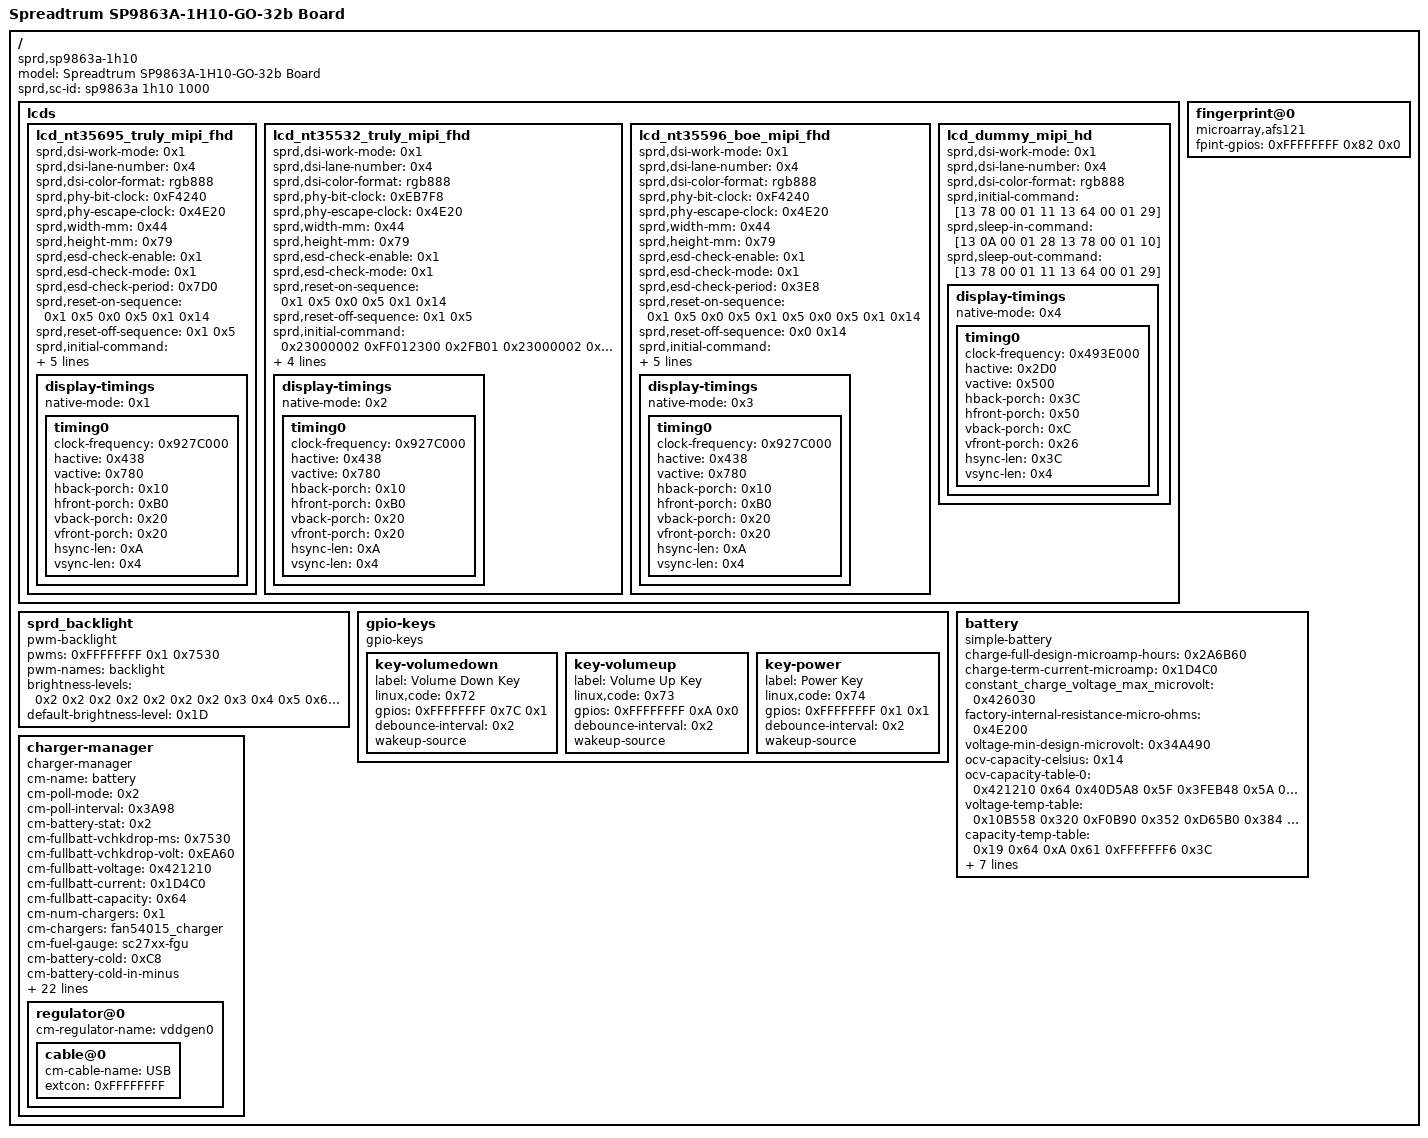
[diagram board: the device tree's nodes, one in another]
/dts-v1/;
// version: 17
// last_comp_version: 16
// boot_cpuid_phys: 0x0

/ {
    model = "Spreadtrum SP9863A-1H10-GO-32b Board";
    compatible = "sprd,sp9863a-1h10", "sprd,sc9863a";
    sprd,sc-id = "sp9863a 1h10 1000";
    fragment {
        target-path = "/";
        __overlay__ {
            lcds {
                lcd_nt35695_truly_mipi_fhd {
                    sprd,dsi-work-mode = <0x1>;
                    sprd,dsi-lane-number = <0x4>;
                    sprd,dsi-color-format = "rgb888";
                    sprd,phy-bit-clock = <0xF4240>;
                    sprd,phy-escape-clock = <0x4E20>;
                    sprd,width-mm = <0x44>;
                    sprd,height-mm = <0x79>;
                    sprd,esd-check-enable = <0x1>;
                    sprd,esd-check-mode = <0x1>;
                    sprd,esd-check-period = <0x7D0>;
                    sprd,reset-on-sequence = <0x1 0x5 0x0 0x5 0x1 0x14>;
                    sprd,reset-off-sequence = <0x1 0x5>;
                    sprd,initial-command = [23 00 00 02 FF 20 23 00 00 02 00 01 23 00 00 02 01 55 23 00 00 02 02 45 23 00 00 02 03 55 23 00 00 02 05 50 23 00 00 02 06 4A 23 00 00 02 07 24 23 00 00 02 08 0C 23 00 00 02 0B 87 23 00 00 02 0C 87 23 00 00 02 0E B0 23 00 00 02 0F B3 23 00 00 02 11 25 23 00 00 02 12 10 23 00 00 02 13 03 23 00 00 02 14 4A 23 00 00 02 15 12 23 00 00 02 16 12 23 00 00 02 30 01 23 00 00 02 58 82 23 00 00 02 59 00 23 00 00 02 5A 02 23 00 00 02 5B 00 23 00 00 02 5C 82 23 00 00 02 5D 82 23 00 00 02 5E 02 23 00 00 02 5F 02 23 00 00 02 72 31 23 00 00 02 FB 01 23 00 00 02 75 00 23 00 00 02 76 00 23 00 00 02 77 00 23 00 00 02 78 06 23 00 00 02 79 00 23 00 00 02 7A 1A 23 00 00 02 7B 00 23 00 00 02 7C 37 23 00 00 02 7D 00 23 00 00 02 7E 5A 23 00 00 02 7F 00 23 00 00 02 80 75 23 00 00 02 81 00 23 00 00 02 82 8D 23 00 00 02 83 00 23 00 00 02 84 A0 23 00 00 02 85 00 23 00 00 02 86 B1 23 00 00 02 87 00 23 00 00 02 88 E4 23 00 00 02 89 01 23 00 00 02 8A 07 23 00 00 02 8B 01 23 00 00 02 8C 36 23 00 00 02 8D 01 23 00 00 02 8E 5D 23 00 00 02 8F 01 23 00 00 02 90 A9 23 00 00 02 91 01 23 00 00 02 92 E1 23 00 00 02 93 01 23 00 00 02 94 E3 23 00 00 02 95 02 23 00 00 02 96 11 23 00 00 02 97 02 23 00 00 02 98 54 23 00 00 02 99 02 23 00 00 02 9A 7F 23 00 00 02 9B 02 23 00 00 02 9C BD 23 00 00 02 9D 02 23 00 00 02 9E E5 23 00 00 02 9F 03 23 00 00 02 A0 1B 23 00 00 02 A2 03 23 00 00 02 A3 25 23 00 00 02 A4 03 23 00 00 02 A5 28 23 00 00 02 A6 03 23 00 00 02 A7 3A 23 00 00 02 A9 03 23 00 00 02 AA 5D 23 00 00 02 AB 03 23 00 00 02 AC A4 23 00 00 02 AD 03 23 00 00 02 AE C1 23 00 00 02 AF 03 23 00 00 02 B0 D3 23 00 00 02 B1 03 23 00 00 02 B2 D8 23 00 00 02 B3 00 23 00 00 02 B4 00 23 00 00 02 B5 00 23 00 00 02 B6 06 23 00 00 02 B7 00 23 00 00 02 B8 1A 23 00 00 02 B9 00 23 00 00 02 BA 37 23 00 00 02 BB 00 23 00 00 02 BC 5A 23 00 00 02 BD 00 23 00 00 02 BE 75 23 00 00 02 BF 00 23 00 00 02 C0 8D 23 00 00 02 C1 00 23 00 00 02 C2 A0 23 00 00 02 C3 00 23 00 00 02 C4 B1 23 00 00 02 C5 00 23 00 00 02 C6 E4 23 00 00 02 C7 01 23 00 00 02 C8 07 23 00 00 02 C9 01 23 00 00 02 CA 36 23 00 00 02 CB 01 23 00 00 02 CC 5D 23 00 00 02 CD 01 23 00 00 02 CE A9 23 00 00 02 CF 01 23 00 00 02 D0 E1 23 00 00 02 D1 01 23 00 00 02 D2 E3 23 00 00 02 D3 02 23 00 00 02 D4 11 23 00 00 02 D5 02 23 00 00 02 D6 54 23 00 00 02 D7 02 23 00 00 02 D8 7F 23 00 00 02 D9 02 23 00 00 02 DA BD 23 00 00 02 DB 02 23 00 00 02 DC E5 23 00 00 02 DD 03 23 00 00 02 DE 1B 23 00 00 02 DF 03 23 00 00 02 E0 25 23 00 00 02 E1 03 23 00 00 02 E2 28 23 00 00 02 E3 03 23 00 00 02 E4 3A 23 00 00 02 E5 03 23 00 00 02 E6 5D 23 00 00 02 E7 03 23 00 00 02 E8 A4 23 00 00 02 E9 03 23 00 00 02 EA C1 23 00 00 02 EB 03 23 00 00 02 EC D3 23 00 00 02 ED 03 23 00 00 02 EE D8 23 00 00 02 EF 00 23 00 00 02 F0 BA 23 00 00 02 F1 00 23 00 00 02 F2 C1 23 00 00 02 F3 00 23 00 00 02 F4 D1 23 00 00 02 F5 00 23 00 00 02 F6 DE 23 00 00 02 F7 00 23 00 00 02 F8 E7 23 00 00 02 F9 00 23 00 00 02 FA F0 23 00 00 02 FF 21 23 00 00 02 00 00 23 00 00 02 01 FA 23 00 00 02 02 01 23 00 00 02 03 03 23 00 00 02 04 01 23 00 00 02 05 0E 23 00 00 02 06 01 23 00 00 02 07 33 23 00 00 02 08 01 23 00 00 02 09 4C 23 00 00 02 0A 01 23 00 00 02 0B 6D 23 00 00 02 0C 01 23 00 00 02 0D 8A 23 00 00 02 0E 01 23 00 00 02 0F C0 23 00 00 02 10 01 23 00 00 02 11 EF 23 00 00 02 12 01 23 00 00 02 13 F1 23 00 00 02 14 02 23 00 00 02 15 20 23 00 00 02 16 02 23 00 00 02 17 63 23 00 00 02 18 02 23 00 00 02 19 91 23 00 00 02 1A 02 23 00 00 02 1B CF 23 00 00 02 1C 02 23 00 00 02 1D F9 23 00 00 02 1E 03 23 00 00 02 1F 31 23 00 00 02 20 03 23 00 00 02 21 3D 23 00 00 02 22 03 23 00 00 02 23 40 23 00 00 02 24 03 23 00 00 02 25 51 23 00 00 02 26 03 23 00 00 02 27 71 23 00 00 02 28 03 23 00 00 02 29 85 23 00 00 02 2A 03 23 00 00 02 2B AB 23 00 00 02 2D 03 23 00 00 02 2F D6 23 00 00 02 30 03 23 00 00 02 31 D8 23 00 00 02 32 00 23 00 00 02 33 BA 23 00 00 02 34 00 23 00 00 02 35 C1 23 00 00 02 36 00 23 00 00 02 37 D1 23 00 00 02 38 00 23 00 00 02 39 DE 23 00 00 02 3A 00 23 00 00 02 3B E7 23 00 00 02 3D 00 23 00 00 02 3F F0 23 00 00 02 40 00 23 00 00 02 41 FA 23 00 00 02 42 01 23 00 00 02 43 03 23 00 00 02 44 01 23 00 00 02 45 0E 23 00 00 02 46 01 23 00 00 02 47 33 23 00 00 02 48 01 23 00 00 02 49 4C 23 00 00 02 4A 01 23 00 00 02 4B 6D 23 00 00 02 4C 01 23 00 00 02 4D 8A 23 00 00 02 4E 01 23 00 00 02 4F C0 23 00 00 02 50 01 23 00 00 02 51 EF 23 00 00 02 52 01 23 00 00 02 53 F1 23 00 00 02 54 02 23 00 00 02 55 20 23 00 00 02 56 02 23 00 00 02 58 63 23 00 00 02 59 02 23 00 00 02 5A 91 23 00 00 02 5B 02 23 00 00 02 5C CF 23 00 00 02 5D 02 23 00 00 02 5E F9 23 00 00 02 5F 03 23 00 00 02 60 31 23 00 00 02 61 03 23 00 00 02 62 3D 23 00 00 02 63 03 23 00 00 02 64 40 23 00 00 02 65 03 23 00 00 02 66 51 23 00 00 02 67 03 23 00 00 02 68 71 23 00 00 02 69 03 23 00 00 02 6A 85 23 00 00 02 6B 03 23 00 00 02 6C AB 23 00 00 02 6D 03 23 00 00 02 6E D6 23 00 00 02 6F 03 23 00 00 02 70 D8 23 00 00 02 71 00 23 00 00 02 72 A7 23 00 00 02 73 00 23 00 00 02 74 AE 23 00 00 02 75 00 23 00 00 02 76 BD 23 00 00 02 77 00 23 00 00 02 78 CA 23 00 00 02 79 00 23 00 00 02 7A D4 23 00 00 02 7B 00 23 00 00 02 7C DD 23 00 00 02 7D 00 23 00 00 02 7E E6 23 00 00 02 7F 00 23 00 00 02 80 EF 23 00 00 02 81 00 23 00 00 02 82 F9 23 00 00 02 83 01 23 00 00 02 84 1D 23 00 00 02 85 01 23 00 00 02 86 36 23 00 00 02 87 01 23 00 00 02 88 5B 23 00 00 02 89 01 23 00 00 02 8A 79 23 00 00 02 8B 01 23 00 00 02 8C BA 23 00 00 02 8D 01 23 00 00 02 8E EA 23 00 00 02 8F 01 23 00 00 02 90 ED 23 00 00 02 91 02 23 00 00 02 92 1B 23 00 00 02 93 02 23 00 00 02 94 5F 23 00 00 02 95 02 23 00 00 02 96 8A 23 00 00 02 97 02 23 00 00 02 98 CC 23 00 00 02 99 02 23 00 00 02 9A FB 23 00 00 02 9B 03 23 00 00 02 9C 61 23 00 00 02 9D 03 23 00 00 02 9E AF 23 00 00 02 9F 03 23 00 00 02 A0 C6 23 00 00 02 A2 03 23 00 00 02 A3 CC 23 00 00 02 A4 03 23 00 00 02 A5 CE 23 00 00 02 A6 03 23 00 00 02 A7 D2 23 00 00 02 A9 03 23 00 00 02 AA D4 23 00 00 02 AB 03 23 00 00 02 AC D7 23 00 00 02 AD 03 23 00 00 02 AE D8 23 00 00 02 AF 00 23 00 00 02 B0 A7 23 00 00 02 B1 00 23 00 00 02 B2 AE 23 00 00 02 B3 00 23 00 00 02 B4 BD 23 00 00 02 B5 00 23 00 00 02 B6 CA 23 00 00 02 B7 00 23 00 00 02 B8 D4 23 00 00 02 B9 00 23 00 00 02 BA DD 23 00 00 02 BB 00 23 00 00 02 BC E6 23 00 00 02 BD 00 23 00 00 02 BE EF 23 00 00 02 BF 00 23 00 00 02 C0 F9 23 00 00 02 C1 01 23 00 00 02 C2 1D 23 00 00 02 C3 01 23 00 00 02 C4 36 23 00 00 02 C5 01 23 00 00 02 C6 5B 23 00 00 02 C7 01 23 00 00 02 C8 79 23 00 00 02 C9 01 23 00 00 02 CA BA 23 00 00 02 CB 01 23 00 00 02 CC EA 23 00 00 02 CD 01 23 00 00 02 CE ED 23 00 00 02 CF 02 23 00 00 02 D0 1B 23 00 00 02 D1 02 23 00 00 02 D2 5F 23 00 00 02 D3 02 23 00 00 02 D4 8A 23 00 00 02 D5 02 23 00 00 02 D6 CC 23 00 00 02 D7 02 23 00 00 02 D8 FB 23 00 00 02 D9 03 23 00 00 02 DA 61 23 00 00 02 DB 03 23 00 00 02 DC AF 23 00 00 02 DD 03 23 00 00 02 DE C6 23 00 00 02 DF 03 23 00 00 02 E0 CC 23 00 00 02 E1 03 23 00 00 02 E2 CE 23 00 00 02 E3 03 23 00 00 02 E4 D2 23 00 00 02 E5 03 23 00 00 02 E6 D4 23 00 00 02 E7 03 23 00 00 02 E8 D7 23 00 00 02 E9 03 23 00 00 02 EA D8 23 00 00 02 FF 24 23 00 00 02 00 01 23 00 00 02 01 0B 23 00 00 02 02 0C 23 00 00 02 03 09 23 00 00 02 04 0A 23 00 00 02 05 1C 23 00 00 02 06 10 23 00 00 02 07 00 23 00 00 02 08 1C 23 00 00 02 09 00 23 00 00 02 0A 00 23 00 00 02 0B 00 23 00 00 02 0C 00 23 00 00 02 0D 13 23 00 00 02 0E 15 23 00 00 02 0F 17 23 00 00 02 10 01 23 00 00 02 11 0B 23 00 00 02 12 0C 23 00 00 02 13 09 23 00 00 02 14 0A 23 00 00 02 15 1C 23 00 00 02 16 10 23 00 00 02 17 10 23 00 00 02 18 1C 23 00 00 02 19 00 23 00 00 02 1A 00 23 00 00 02 1B 00 23 00 00 02 1C 00 23 00 00 02 1D 13 23 00 00 02 1E 15 23 00 00 02 1F 17 23 00 00 02 20 00 23 00 00 02 21 03 23 00 00 02 22 01 23 00 00 02 23 4A 23 00 00 02 24 4A 23 00 00 02 25 6D 23 00 00 02 26 40 23 00 00 02 27 40 23 00 00 02 BD 20 23 00 00 02 B6 22 23 00 00 02 B7 24 23 00 00 02 B8 07 23 00 00 02 B9 07 23 00 00 02 C1 6D 23 00 00 02 BE 07 23 00 00 02 BF 07 23 00 00 02 29 D8 23 00 00 02 2A 2A 23 00 00 02 4B 04 23 00 00 02 4C 12 23 00 00 02 4D 00 23 00 00 02 4E 22 23 00 00 02 4F 22 23 00 00 02 50 00 23 00 00 02 51 61 23 00 00 02 52 01 23 00 00 02 53 08 23 00 00 02 56 08 23 00 00 02 54 8A 23 00 00 02 58 8A 23 00 00 02 55 6D 23 00 00 02 5B 43 23 00 00 02 5C 00 23 00 00 02 5F 73 23 00 00 02 60 73 23 00 00 02 63 22 23 00 00 02 64 00 23 00 00 02 67 08 23 00 00 02 68 04 23 00 00 02 7A 80 23 00 00 02 7B 91 23 00 00 02 7C D8 23 00 00 02 7D 60 23 00 00 02 75 20 23 00 00 02 7F 20 23 00 00 02 74 10 23 00 00 02 7E 10 23 00 00 02 93 06 23 00 00 02 94 06 23 00 00 02 B3 00 23 00 00 02 B4 00 23 00 00 02 B5 00 23 00 00 02 78 00 23 00 00 02 79 00 23 00 00 02 80 00 23 00 00 02 83 00 23 00 00 02 84 04 23 00 00 02 8A 33 23 00 00 02 9B 0F 23 00 00 02 8B F0 23 00 00 02 E3 00 23 00 00 02 FB 01 23 00 00 02 EC 00 23 00 00 02 FF 10 29 00 00 04 3B 03 24 20 23 00 00 02 35 00 23 00 00 02 BB 03 29 00 00 03 51 FF 00 23 00 00 02 53 2C 23 00 00 02 55 00 13 50 00 01 11 13 14 00 01 29];
                    sprd,sleep-in-command = [13 01 00 01 00 13 0A 00 01 28 13 78 00 01 10 23 0A 00 02 4F 01];
                    sprd,sleep-out-command = [13 50 00 01 11 13 14 00 01 29];
                    phandle = <0x1F>;
                    display-timings {
                        native-mode = <0x1>;
                        timing0 {
                            clock-frequency = <0x927C000>;
                            hactive = <0x438>;
                            vactive = <0x780>;
                            hback-porch = <0x10>;
                            hfront-porch = <0xB0>;
                            vback-porch = <0x20>;
                            vfront-porch = <0x20>;
                            hsync-len = <0xA>;
                            vsync-len = <0x4>;
                            phandle = <0x1>;
                        };
                    };
                };
                lcd_nt35532_truly_mipi_fhd {
                    sprd,dsi-work-mode = <0x1>;
                    sprd,dsi-lane-number = <0x4>;
                    sprd,dsi-color-format = "rgb888";
                    sprd,phy-bit-clock = <0xEB7F8>;
                    sprd,phy-escape-clock = <0x4E20>;
                    sprd,width-mm = <0x44>;
                    sprd,height-mm = <0x79>;
                    sprd,esd-check-enable = <0x1>;
                    sprd,esd-check-mode = <0x1>;
                    sprd,reset-on-sequence = <0x1 0x5 0x0 0x5 0x1 0x14>;
                    sprd,reset-off-sequence = <0x1 0x5>;
                    sprd,initial-command = <0x23000002 0xFF012300 0x2FB01 0x23000002 0x12300 0x20144 0x23000002 0x2592300 0x2040C 0x23000002 0x52B2300 0x20664 0x23000002 0x7C62300 0x20D89 0x23000002 0xE892300 0x20FE0 0x23000002 0x10032300 0x2115A 0x23000002 0x125A2300 0x2137E 0x23000002 0x147E2300 0x21560 0x23000002 0x16132300 0x21713 0x23000002 0x1CA32300 0x26E80 0x23000002 0x60772300 0x26813 0x23000002 0x75002300 0x27677 0x23000002 0x77002300 0x27878 0x23000002 0x79002300 0x27AB0 0x23000002 0x7B002300 0x27CCC 0x23000002 0x7D002300 0x27EE3 0x23000002 0x7F002300 0x280F6 0x23000002 0x81012300 0x28206 0x23000002 0x83012300 0x28415 0x23000002 0x85012300 0x28622 0x23000002 0x87012300 0x2884E 0x23000002 0x89012300 0x28A71 0x23000002 0x8B012300 0x28CA7 0x23000002 0x8D012300 0x28ED2 0x23000002 0x8F022300 0x29014 0x23000002 0x91022300 0x29249 0x23000002 0x93022300 0x2944B 0x23000002 0x95022300 0x2967D 0x23000002 0x97022300 0x298B6 0x23000002 0x99022300 0x29AD9 0x23000002 0x9B032300 0x29C0D 0x23000002 0x9D032300 0x29E2A 0x23000002 0x9F032300 0x2A051 0x23000002 0xA2032300 0x2A35D 0x23000002 0xA4032300 0x2A56A 0x23000002 0xA6032300 0x2A778 0x23000002 0xA9032300 0x2AA89 0x23000002 0xAB032300 0x2AC9E 0x23000002 0xAD032300 0x2AEB7 0x23000002 0xAF032300 0x2B0CE 0x23000002 0xB1032300 0x2B2D1 0x23000002 0xB3002300 0x2B418 0x23000002 0xB5002300 0x2B66A 0x23000002 0xB7002300 0x2B8B0 0x23000002 0xB9002300 0x2BACC 0x23000002 0xBB002300 0x2BCE3 0x23000002 0xBD002300 0x2BEF6 0x23000002 0xBF012300 0x2C006 0x23000002 0xC1012300 0x2C215 0x23000002 0xC3012300 0x2C422 0x23000002 0xC5012300 0x2C64E 0x23000002 0xC7012300 0x2C871 0x23000002 0xC9012300 0x2CAA7 0x23000002 0xCB012300 0x2CCD2 0x23000002 0xCD022300 0x2CE14 0x23000002 0xCF022300 0x2D049 0x23000002 0xD1022300 0x2D24B 0x23000002 0xD3022300 0x2D47D 0x23000002 0xD5022300 0x2D6B6 0x23000002 0xD7022300 0x2D8D9 0x23000002 0xD9032300 0x2DA0D 0x23000002 0xDB032300 0x2DC2A 0x23000002 0xDD032300 0x2DE51 0x23000002 0xDF032300 0x2E05D 0x23000002 0xE1032300 0x2E26A 0x23000002 0xE3032300 0x2E478 0x23000002 0xE5032300 0x2E689 0x23000002 0xE7032300 0x2E89E 0x23000002 0xE9032300 0x2EAB7 0x23000002 0xEB032300 0x2ECCE 0x23000002 0xED032300 0x2EED1 0x23000002 0xEF002300 0x2F077 0x23000002 0xF1002300 0x2F278 0x23000002 0xF3002300 0x2F4B0 0x23000002 0xF5002300 0x2F6CC 0x23000002 0xF7002300 0x2F8E3 0x23000002 0xF9002300 0x2FAF6 0x23000002 0xFF022300 0x2FB01 0x23000002 0x12300 0x20106 0x23000002 0x2012300 0x20315 0x23000002 0x4012300 0x20522 0x23000002 0x6012300 0x2074E 0x23000002 0x8012300 0x20971 0x23000002 0xA012300 0x20BA7 0x23000002 0xC012300 0x20DD2 0x23000002 0xE022300 0x20F14 0x23000002 0x10022300 0x21149 0x23000002 0x12022300 0x2134B 0x23000002 0x14022300 0x2157D 0x23000002 0x16022300 0x217B6 0x23000002 0x18022300 0x219D9 0x23000002 0x1A032300 0x21B0D 0x23000002 0x1C032300 0x21D2A 0x23000002 0x1E032300 0x21F51 0x23000002 0x20032300 0x2215D 0x23000002 0x22032300 0x2236A 0x23000002 0x24032300 0x22578 0x23000002 0x26032300 0x22789 0x23000002 0x28032300 0x2299E 0x23000002 0x2A032300 0x22BB7 0x23000002 0x2D032300 0x22FCE 0x23000002 0x30032300 0x231D1 0x23000002 0x32002300 0x23318 0x23000002 0x34002300 0x2356A 0x23000002 0x36002300 0x237B0 0x23000002 0x38002300 0x239CC 0x23000002 0x3A002300 0x23BE3 0x23000002 0x3D002300 0x23FF6 0x23000002 0x40012300 0x24106 0x23000002 0x42012300 0x24315 0x23000002 0x44012300 0x24522 0x23000002 0x46012300 0x2474E 0x23000002 0x48012300 0x24971 0x23000002 0x4A012300 0x24BA7 0x23000002 0x4C012300 0x24DD2 0x23000002 0x4E022300 0x24F14 0x23000002 0x50022300 0x25149 0x23000002 0x52022300 0x2534B 0x23000002 0x54022300 0x2557D 0x23000002 0x56022300 0x258B6 0x23000002 0x59022300 0x25AD9 0x23000002 0x5B032300 0x25C0D 0x23000002 0x5D032300 0x25E2A 0x23000002 0x5F032300 0x26051 0x23000002 0x61032300 0x2625D 0x23000002 0x63032300 0x2646A 0x23000002 0x65032300 0x26678 0x23000002 0x67032300 0x26889 0x23000002 0x69032300 0x26A9E 0x23000002 0x6B032300 0x26CB7 0x23000002 0x6D032300 0x26ECE 0x23000002 0x6F032300 0x270D1 0x23000002 0x71002300 0x27277 0x23000002 0x73002300 0x27478 0x23000002 0x75002300 0x276B0 0x23000002 0x77002300 0x278CC 0x23000002 0x79002300 0x27AE3 0x23000002 0x7B002300 0x27CF6 0x23000002 0x7D012300 0x27E06 0x23000002 0x7F012300 0x28015 0x23000002 0x81012300 0x28222 0x23000002 0x83012300 0x2844E 0x23000002 0x85012300 0x28671 0x23000002 0x87012300 0x288A7 0x23000002 0x89012300 0x28AD2 0x23000002 0x8B022300 0x28C14 0x23000002 0x8D022300 0x28E49 0x23000002 0x8F022300 0x2904B 0x23000002 0x91022300 0x2927D 0x23000002 0x93022300 0x294B6 0x23000002 0x95022300 0x296D9 0x23000002 0x97032300 0x2980D 0x23000002 0x99032300 0x29A2A 0x23000002 0x9B032300 0x29C51 0x23000002 0x9D032300 0x29E5D 0x23000002 0x9F032300 0x2A06A 0x23000002 0xA2032300 0x2A378 0x23000002 0xA4032300 0x2A589 0x23000002 0xA6032300 0x2A79E 0x23000002 0xA9032300 0x2AAB7 0x23000002 0xAB032300 0x2ACCE 0x23000002 0xAD032300 0x2AED1 0x23000002 0xAF002300 0x2B018 0x23000002 0xB1002300 0x2B26A 0x23000002 0xB3002300 0x2B4B0 0x23000002 0xB5002300 0x2B6CC 0x23000002 0xB7002300 0x2B8E3 0x23000002 0xB9002300 0x2BAF6 0x23000002 0xBB012300 0x2BC06 0x23000002 0xBD012300 0x2BE15 0x23000002 0xBF012300 0x2C022 0x23000002 0xC1012300 0x2C24E 0x23000002 0xC3012300 0x2C471 0x23000002 0xC5012300 0x2C6A7 0x23000002 0xC7012300 0x2C8D2 0x23000002 0xC9022300 0x2CA14 0x23000002 0xCB022300 0x2CC49 0x23000002 0xCD022300 0x2CE4B 0x23000002 0xCF022300 0x2D07D 0x23000002 0xD1022300 0x2D2B6 0x23000002 0xD3022300 0x2D4D9 0x23000002 0xD5032300 0x2D60D 0x23000002 0xD7032300 0x2D82A 0x23000002 0xD9032300 0x2DA51 0x23000002 0xDB032300 0x2DC5D 0x23000002 0xDD032300 0x2DE6A 0x23000002 0xDF032300 0x2E078 0x23000002 0xE1032300 0x2E289 0x23000002 0xE3032300 0x2E49E 0x23000002 0xE5032300 0x2E6B7 0x23000002 0xE7032300 0x2E8CE 0x23000002 0xE9032300 0x2EAD1 0x23000002 0xFF052300 0x2FB01 0x23000002 0x382300 0x20138 0x23000002 0x2072300 0x20340 0x23000002 0x4402300 0x20525 0x23000002 0x61D2300 0x20723 0x23000002 0x81B2300 0x20921 0x23000002 0xA192300 0x20B1F 0x23000002 0xC172300 0x20D05 0x23000002 0xE042300 0x20F0F 0x23000002 0x10382300 0x21138 0x23000002 0x12382300 0x21338 0x23000002 0x14382300 0x21538 0x23000002 0x16062300 0x21740 0x23000002 0x18402300 0x21924 0x23000002 0x1A1C2300 0x21B22 0x23000002 0x1C1A2300 0x21D20 0x23000002 0x1E182300 0x21F1E 0x23000002 0x20162300 0x22105 0x23000002 0x22042300 0x2230E 0x23000002 0x24382300 0x22538 0x23000002 0x26382300 0x22738 0x23000002 0x28382300 0x22938 0x23000002 0x2A0E2300 0x22B40 0x23000002 0x2D402300 0x22F16 0x23000002 0x301E2300 0x23118 0x23000002 0x32202300 0x2331A 0x23000002 0x34222300 0x2351C 0x23000002 0x36242300 0x23705 0x23000002 0x38042300 0x23906 0x23000002 0x3A382300 0x23B38 0x23000002 0x3D382300 0x23F38 0x23000002 0x40382300 0x24138 0x23000002 0x420F2300 0x24340 0x23000002 0x44402300 0x24517 0x23000002 0x461F2300 0x24719 0x23000002 0x48212300 0x2491B 0x23000002 0x4A232300 0x24B1D 0x23000002 0x4C252300 0x24D05 0x23000002 0x4E042300 0x24F07 0x23000002 0x50382300 0x25138 0x23000002 0x52382300 0x25338 0x23000002 0x5B0A2300 0x25C0A 0x23000002 0x630A2300 0x26415 0x23000002 0x68242300 0x26924 0x23000002 0x907B2300 0x29110 0x23000002 0x92152300 0x27E10 0x23000002 0x7F102300 0x28000 0x23000002 0x98002300 0x29900 0x23000002 0x542E2300 0x25938 0x23000002 0x5D012300 0x25E27 0x23000002 0x62392300 0x26688 0x23000002 0x67112300 0x26A0E 0x23000002 0x6B202300 0x26C08 0x23000002 0x6D002300 0x27D01 0x23000002 0xB7012300 0x2B80A 0x23000002 0xBA132300 0x2BC01 0x23000002 0xBD552300 0x2BE38 0x23000002 0xBF442300 0x2CF88 0x23000002 0xC8002300 0x2C955 0x23000002 0xCA002300 0x2CB55 0x23000002 0xCCA22300 0x2CE88 0x23000002 0xCF882300 0x2D000 0x23000002 0xD1002300 0x2D300 0x23000002 0xD5002300 0x2D622 0x23000002 0xD7312300 0x2D87E 0x23000002 0xFF002300 0x2FB01 0x23000002 0xD3242300 0x2D420 0x23000002 0xD55A2300 0x2D650 0x23000002 0xD7002300 0x23500 0x23000002 0xFF002300 0x2FB01 0x23000002 0x51FF2300 0x2532C 0x23000002 0x36001378 0x11113 0xA000129>;
                    sprd,sleep-in-command = [13 01 00 01 00 13 0A 00 01 28 13 78 00 01 10 23 0A 00 02 4F 01];
                    sprd,sleep-out-command = [13 78 00 01 11 13 32 00 01 29];
                    phandle = <0x20>;
                    display-timings {
                        native-mode = <0x2>;
                        timing0 {
                            clock-frequency = <0x927C000>;
                            hactive = <0x438>;
                            vactive = <0x780>;
                            hback-porch = <0x10>;
                            hfront-porch = <0xB0>;
                            vback-porch = <0x20>;
                            vfront-porch = <0x20>;
                            hsync-len = <0xA>;
                            vsync-len = <0x4>;
                            phandle = <0x2>;
                        };
                    };
                };
                lcd_nt35596_boe_mipi_fhd {
                    sprd,dsi-work-mode = <0x1>;
                    sprd,dsi-lane-number = <0x4>;
                    sprd,dsi-color-format = "rgb888";
                    sprd,phy-bit-clock = <0xF4240>;
                    sprd,phy-escape-clock = <0x4E20>;
                    sprd,width-mm = <0x44>;
                    sprd,height-mm = <0x79>;
                    sprd,esd-check-enable = <0x1>;
                    sprd,esd-check-mode = <0x1>;
                    sprd,esd-check-period = <0x3E8>;
                    sprd,reset-on-sequence = <0x1 0x5 0x0 0x5 0x1 0x5 0x0 0x5 0x1 0x14>;
                    sprd,reset-off-sequence = <0x0 0x14>;
                    sprd,initial-command = [23 00 00 02 FF EE 23 0A 00 02 18 40 23 14 00 02 18 00 23 00 00 02 FF 01 23 00 00 02 FB 01 23 00 00 02 00 01 23 00 00 02 01 55 23 00 00 02 02 40 23 00 00 02 05 40 23 00 00 02 06 94 23 00 00 02 07 94 23 00 00 02 08 0C 23 00 00 02 11 19 23 00 00 02 12 19 23 00 00 02 13 03 23 00 00 02 14 94 23 00 00 02 15 15 23 00 00 02 16 15 23 00 00 02 6D 22 23 00 00 02 0B AF 23 00 00 02 0C AF 23 00 00 02 0E AB 23 00 00 02 0F A4 23 00 00 02 58 82 23 00 00 02 59 02 23 00 00 02 5A 02 23 00 00 02 5B 02 23 00 00 02 5C 82 23 00 00 02 5D 82 23 00 00 02 5E 02 23 00 00 02 5F 02 23 00 00 02 75 00 23 00 00 02 76 00 23 00 00 02 77 00 23 00 00 02 78 11 23 00 00 02 79 00 23 00 00 02 7A 30 23 00 00 02 7B 00 23 00 00 02 7C 4A 23 00 00 02 7D 00 23 00 00 02 7E 62 23 00 00 02 7F 00 23 00 00 02 80 78 23 00 00 02 81 00 23 00 00 02 82 8C 23 00 00 02 83 00 23 00 00 02 84 9E 23 00 00 02 85 00 23 00 00 02 86 AE 23 00 00 02 87 00 23 00 00 02 88 E4 23 00 00 02 89 01 23 00 00 02 8A 0E 23 00 00 02 8B 01 23 00 00 02 8C 4C 23 00 00 02 8D 01 23 00 00 02 8E 7B 23 00 00 02 8F 01 23 00 00 02 90 C2 23 00 00 02 91 01 23 00 00 02 92 FB 23 00 00 02 93 01 23 00 00 02 94 FC 23 00 00 02 95 02 23 00 00 02 96 34 23 00 00 02 97 02 23 00 00 02 98 79 23 00 00 02 99 02 23 00 00 02 9A A4 23 00 00 02 9B 02 23 00 00 02 9C DD 23 00 00 02 9D 03 23 00 00 02 9E 05 23 00 00 02 9F 03 23 00 00 02 A0 39 23 00 00 02 A2 03 23 00 00 02 A3 48 23 00 00 02 A4 03 23 00 00 02 A5 58 23 00 00 02 A6 03 23 00 00 02 A7 6A 23 00 00 02 A9 03 23 00 00 02 AA 7F 23 00 00 02 AB 03 23 00 00 02 AC 98 23 00 00 02 AD 03 23 00 00 02 AE B7 23 00 00 02 AF 03 23 00 00 02 B0 D7 23 00 00 02 B1 03 23 00 00 02 B2 FF 23 00 00 02 B3 00 23 00 00 02 B4 00 23 00 00 02 B5 00 23 00 00 02 B6 11 23 00 00 02 B7 00 23 00 00 02 B8 30 23 00 00 02 B9 00 23 00 00 02 BA 4A 23 00 00 02 BB 00 23 00 00 02 BC 62 23 00 00 02 BD 00 23 00 00 02 BE 78 23 00 00 02 BF 00 23 00 00 02 C0 8C 23 00 00 02 C1 00 23 00 00 02 C2 9E 23 00 00 02 C3 00 23 00 00 02 C4 AE 23 00 00 02 C5 00 23 00 00 02 C6 E4 23 00 00 02 C7 01 23 00 00 02 C8 0E 23 00 00 02 C9 01 23 00 00 02 CA 4C 23 00 00 02 CB 01 23 00 00 02 CC 7B 23 00 00 02 CD 01 23 00 00 02 CE C2 23 00 00 02 CF 01 23 00 00 02 D0 FB 23 00 00 02 D1 01 23 00 00 02 D2 FC 23 00 00 02 D3 02 23 00 00 02 D4 34 23 00 00 02 D5 02 23 00 00 02 D6 79 23 00 00 02 D7 02 23 00 00 02 D8 A4 23 00 00 02 D9 02 23 00 00 02 DA DD 23 00 00 02 DB 03 23 00 00 02 DC 05 23 00 00 02 DD 03 23 00 00 02 DE 39 23 00 00 02 DF 03 23 00 00 02 E0 48 23 00 00 02 E1 03 23 00 00 02 E2 58 23 00 00 02 E3 03 23 00 00 02 E4 6A 23 00 00 02 E5 03 23 00 00 02 E6 7F 23 00 00 02 E7 03 23 00 00 02 E8 98 23 00 00 02 E9 03 23 00 00 02 EA B7 23 00 00 02 EB 03 23 00 00 02 EC D7 23 00 00 02 ED 03 23 00 00 02 EE FF 23 00 00 02 EF 00 23 00 00 02 F0 00 23 00 00 02 F1 00 23 00 00 02 F2 11 23 00 00 02 F3 00 23 00 00 02 F4 30 23 00 00 02 F5 00 23 00 00 02 F6 4A 23 00 00 02 F7 00 23 00 00 02 F8 62 23 00 00 02 F9 00 23 00 00 02 FA 78 23 00 00 02 FF 02 23 00 00 02 FB 01 23 00 00 02 00 00 23 00 00 02 01 8C 23 00 00 02 02 00 23 00 00 02 03 9E 23 00 00 02 04 00 23 00 00 02 05 AE 23 00 00 02 06 00 23 00 00 02 07 E4 23 00 00 02 08 01 23 00 00 02 09 0E 23 00 00 02 0A 01 23 00 00 02 0B 4C 23 00 00 02 0C 01 23 00 00 02 0D 7B 23 00 00 02 0E 01 23 00 00 02 0F C2 23 00 00 02 10 01 23 00 00 02 11 FB 23 00 00 02 12 01 23 00 00 02 13 FC 23 00 00 02 14 02 23 00 00 02 15 34 23 00 00 02 16 02 23 00 00 02 17 79 23 00 00 02 18 02 23 00 00 02 19 A4 23 00 00 02 1A 02 23 00 00 02 1B DD 23 00 00 02 1C 03 23 00 00 02 1D 05 23 00 00 02 1E 03 23 00 00 02 1F 39 23 00 00 02 20 03 23 00 00 02 21 48 23 00 00 02 22 03 23 00 00 02 23 58 23 00 00 02 24 03 23 00 00 02 25 6A 23 00 00 02 26 03 23 00 00 02 27 7F 23 00 00 02 28 03 23 00 00 02 29 98 23 00 00 02 2A 03 23 00 00 02 2B B7 23 00 00 02 2D 03 23 00 00 02 2F D7 23 00 00 02 30 03 23 00 00 02 31 FF 23 00 00 02 32 00 23 00 00 02 33 00 23 00 00 02 34 00 23 00 00 02 35 11 23 00 00 02 36 00 23 00 00 02 37 30 23 00 00 02 38 00 23 00 00 02 39 4A 23 00 00 02 3A 00 23 00 00 02 3B 62 23 00 00 02 3D 00 23 00 00 02 3F 78 23 00 00 02 40 00 23 00 00 02 41 8C 23 00 00 02 42 00 23 00 00 02 43 9E 23 00 00 02 44 00 23 00 00 02 45 AE 23 00 00 02 46 00 23 00 00 02 47 E4 23 00 00 02 48 01 23 00 00 02 49 0E 23 00 00 02 4A 01 23 00 00 02 4B 4C 23 00 00 02 4C 01 23 00 00 02 4D 7B 23 00 00 02 4E 01 23 00 00 02 4F C2 23 00 00 02 50 01 23 00 00 02 51 FB 23 00 00 02 52 01 23 00 00 02 53 FC 23 00 00 02 54 02 23 00 00 02 55 34 23 00 00 02 56 02 23 00 00 02 58 79 23 00 00 02 59 02 23 00 00 02 5A A4 23 00 00 02 5B 02 23 00 00 02 5C DD 23 00 00 02 5D 03 23 00 00 02 5E 05 23 00 00 02 5F 03 23 00 00 02 60 39 23 00 00 02 61 03 23 00 00 02 62 48 23 00 00 02 63 03 23 00 00 02 64 58 23 00 00 02 65 03 23 00 00 02 66 6A 23 00 00 02 67 03 23 00 00 02 68 7F 23 00 00 02 69 03 23 00 00 02 6A 98 23 00 00 02 6B 03 23 00 00 02 6C B7 23 00 00 02 6D 03 23 00 00 02 6E D7 23 00 00 02 6F 03 23 00 00 02 70 FF 23 00 00 02 71 00 23 00 00 02 72 00 23 00 00 02 73 00 23 00 00 02 74 11 23 00 00 02 75 00 23 00 00 02 76 30 23 00 00 02 77 00 23 00 00 02 78 4A 23 00 00 02 79 00 23 00 00 02 7A 62 23 00 00 02 7B 00 23 00 00 02 7C 78 23 00 00 02 7D 00 23 00 00 02 7E 8C 23 00 00 02 7F 00 23 00 00 02 80 9E 23 00 00 02 81 00 23 00 00 02 82 AE 23 00 00 02 83 00 23 00 00 02 84 E4 23 00 00 02 85 01 23 00 00 02 86 0E 23 00 00 02 87 01 23 00 00 02 88 4C 23 00 00 02 89 01 23 00 00 02 8A 7B 23 00 00 02 8B 01 23 00 00 02 8C C2 23 00 00 02 8D 01 23 00 00 02 8E FB 23 00 00 02 8F 01 23 00 00 02 90 FC 23 00 00 02 91 02 23 00 00 02 92 34 23 00 00 02 93 02 23 00 00 02 94 79 23 00 00 02 95 02 23 00 00 02 96 A4 23 00 00 02 97 02 23 00 00 02 98 DD 23 00 00 02 99 03 23 00 00 02 9A 05 23 00 00 02 9B 03 23 00 00 02 9C 39 23 00 00 02 9D 03 23 00 00 02 9E 48 23 00 00 02 9F 03 23 00 00 02 A0 58 23 00 00 02 A2 03 23 00 00 02 A3 6A 23 00 00 02 A4 03 23 00 00 02 A5 7F 23 00 00 02 A6 03 23 00 00 02 A7 98 23 00 00 02 A9 03 23 00 00 02 AA B7 23 00 00 02 AB 03 23 00 00 02 AC D7 23 00 00 02 AD 03 23 00 00 02 AE FF 23 00 00 02 AF 00 23 00 00 02 B0 00 23 00 00 02 B1 00 23 00 00 02 B2 11 23 00 00 02 B3 00 23 00 00 02 B4 30 23 00 00 02 B5 00 23 00 00 02 B6 4A 23 00 00 02 B7 00 23 00 00 02 B8 62 23 00 00 02 B9 00 23 00 00 02 BA 78 23 00 00 02 BB 00 23 00 00 02 BC 8C 23 00 00 02 BD 00 23 00 00 02 BE 9E 23 00 00 02 BF 00 23 00 00 02 C0 AE 23 00 00 02 C1 00 23 00 00 02 C2 E4 23 00 00 02 C3 01 23 00 00 02 C4 0E 23 00 00 02 C5 01 23 00 00 02 C6 4C 23 00 00 02 C7 01 23 00 00 02 C8 7B 23 00 00 02 C9 01 23 00 00 02 CA C2 23 00 00 02 CB 01 23 00 00 02 CC FB 23 00 00 02 CD 01 23 00 00 02 CE FC 23 00 00 02 CF 02 23 00 00 02 D0 34 23 00 00 02 D1 02 23 00 00 02 D2 79 23 00 00 02 D3 02 23 00 00 02 D4 A4 23 00 00 02 D5 02 23 00 00 02 D6 DD 23 00 00 02 D7 03 23 00 00 02 D8 05 23 00 00 02 D9 03 23 00 00 02 DA 39 23 00 00 02 DB 03 23 00 00 02 DC 48 23 00 00 02 DD 03 23 00 00 02 DE 58 23 00 00 02 DF 03 23 00 00 02 E0 6A 23 00 00 02 E1 03 23 00 00 02 E2 7F 23 00 00 02 E3 03 23 00 00 02 E4 98 23 00 00 02 E5 03 23 00 00 02 E6 B7 23 00 00 02 E7 03 23 00 00 02 E8 D7 23 00 00 02 E9 03 23 00 00 02 EA FF 23 00 00 02 FF 05 23 00 00 02 FB 01 23 00 00 02 00 00 23 00 00 02 01 01 23 00 00 02 02 0B 23 00 00 02 03 0C 23 00 00 02 04 00 23 00 00 02 05 03 23 00 00 02 06 00 23 00 00 02 07 04 23 00 00 02 08 00 23 00 00 02 09 00 23 00 00 02 0A 00 23 00 00 02 0B 00 23 00 00 02 0C 00 23 00 00 02 0D 17 23 00 00 02 0E 15 23 00 00 02 0F 13 23 00 00 02 10 00 23 00 00 02 11 01 23 00 00 02 12 0B 23 00 00 02 13 0C 23 00 00 02 14 00 23 00 00 02 15 03 23 00 00 02 16 00 23 00 00 02 17 04 23 00 00 02 18 00 23 00 00 02 19 00 23 00 00 02 1A 00 23 00 00 02 1B 00 23 00 00 02 1C 00 23 00 00 02 1D 17 23 00 00 02 1E 15 23 00 00 02 1F 13 23 00 00 02 20 09 23 00 00 02 21 02 23 00 00 02 22 00 23 00 00 02 23 00 23 00 00 02 24 00 23 00 00 02 25 3D 23 00 00 02 29 38 23 00 00 02 2A 2B 23 00 00 02 2F 02 23 00 00 02 30 01 23 00 00 02 31 49 23 00 00 02 32 23 23 00 00 02 33 01 23 00 00 02 34 05 23 00 00 02 35 74 23 00 00 02 36 00 23 00 00 02 37 2D 23 00 00 02 38 08 23 00 00 02 92 94 23 00 00 02 5B 00 23 00 00 02 5F 1D 23 00 00 02 63 00 23 00 00 02 67 04 23 00 00 02 6C 55 23 00 00 02 7A 00 23 00 00 02 7B A2 23 00 00 02 7C D8 23 00 00 02 7D 50 23 00 00 02 7E 0A 23 00 00 02 7F 1C 23 00 00 02 81 06 23 00 00 02 82 02 23 00 00 02 84 03 23 00 00 02 85 05 23 00 00 02 C5 20 23 00 00 02 80 00 23 00 00 02 83 00 23 00 00 02 93 08 23 00 00 02 94 0A 23 00 00 02 8A 33 23 00 00 02 A4 0F 23 00 00 02 9B 0F 23 00 00 02 9D B0 23 00 00 02 E7 83 23 00 00 02 E3 02 23 00 00 02 FF 00 23 00 00 02 D2 03 23 00 00 02 D3 24 23 00 00 02 D4 20 23 00 00 02 35 00 23 00 00 02 BA 03 13 78 00 01 11 13 64 00 01 29];
                    sprd,sleep-in-command = <0x130A0001 0x28137800 0x110230A 0x24F01>;
                    sprd,sleep-out-command = [13 78 00 01 11 13 64 00 01 29];
                    phandle = <0x21>;
                    display-timings {
                        native-mode = <0x3>;
                        timing0 {
                            clock-frequency = <0x927C000>;
                            hactive = <0x438>;
                            vactive = <0x780>;
                            hback-porch = <0x10>;
                            hfront-porch = <0xB0>;
                            vback-porch = <0x20>;
                            vfront-porch = <0x20>;
                            hsync-len = <0xA>;
                            vsync-len = <0x4>;
                            phandle = <0x3>;
                        };
                    };
                };
                lcd_dummy_mipi_hd {
                    sprd,dsi-work-mode = <0x1>;
                    sprd,dsi-lane-number = <0x4>;
                    sprd,dsi-color-format = "rgb888";
                    sprd,initial-command = [13 78 00 01 11 13 64 00 01 29];
                    sprd,sleep-in-command = [13 0A 00 01 28 13 78 00 01 10];
                    sprd,sleep-out-command = [13 78 00 01 11 13 64 00 01 29];
                    phandle = <0x22>;
                    display-timings {
                        native-mode = <0x4>;
                        timing0 {
                            clock-frequency = <0x493E000>;
                            hactive = <0x2D0>;
                            vactive = <0x500>;
                            hback-porch = <0x3C>;
                            hfront-porch = <0x50>;
                            vback-porch = <0xC>;
                            vfront-porch = <0x26>;
                            hsync-len = <0x3C>;
                            vsync-len = <0x4>;
                            phandle = <0x4>;
                        };
                    };
                };
            };
            fingerprint@0 {
                compatible = "microarray,afs121";
                fpint-gpios = <0xFFFFFFFF 0x82 0x0>;
            };
            sprd_backlight {
                compatible = "pwm-backlight";
                pwms = <0xFFFFFFFF 0x1 0x7530>;
                pwm-names = "backlight";
                brightness-levels = <0x2 0x2 0x2 0x2 0x2 0x2 0x2 0x3 0x4 0x5 0x6 0x7 0x8 0x9 0xA 0xB 0xC 0xD 0xE 0xF 0x10 0x11 0x12 0x13 0x14 0x15 0x16 0x17 0x18 0x19 0x1A 0x1B 0x1C 0x1D 0x1E 0x1F 0x20 0x21 0x22 0x23 0x24 0x25 0x26 0x27 0x28 0x29 0x2A 0x2B 0x2C 0x2D 0x2E 0x2F 0x30 0x31 0x32 0x33 0x34 0x35 0x36 0x37 0x38 0x39 0x3A 0x3B 0x3C 0x3D 0x3E 0x3F 0x40 0x41 0x42 0x43 0x44 0x45 0x46 0x47 0x48 0x49 0x4A 0x4B 0x4C 0x4D 0x4E 0x4F 0x50 0x51 0x52 0x53 0x54 0x55 0x56 0x57 0x58 0x59 0x5A 0x5B 0x5C 0x5D 0x5E 0x5F 0x60 0x61 0x62 0x63 0x64 0x65 0x66 0x67 0x68 0x69 0x6A 0x6B 0x6C 0x6D 0x6E 0x6F 0x70 0x71 0x72 0x73 0x74 0x75 0x76 0x77 0x78 0x79 0x7A 0x7B 0x7C 0x7D 0x7E 0x7F 0x80 0x81 0x82 0x83 0x84 0x85 0x86 0x87 0x88 0x89 0x8A 0x8B 0x8C 0x8D 0x8E 0x8F 0x90 0x91 0x92 0x93 0x94 0x95 0x96 0x97 0x98 0x99 0x9A 0x9B 0x9C 0x9D 0x9E 0x9F 0xA0 0xA1 0xA2 0xA3 0xA4 0xA5 0xA6 0xA7 0xA8 0xA9 0xAA 0xAB 0xAC 0xAD 0xAE 0xAF 0xB0 0xB1 0xB2 0xB3 0xB4 0xB5 0xB6 0xB7 0xB8 0xB9 0xBA 0xBB 0xBC 0xBD 0xBE 0xBF 0xC0 0xC1 0xC2 0xC3 0xC4 0xC5 0xC6 0xC7 0xC8 0xC9 0xCA 0xCB 0xCC 0xCD 0xCE 0xCF 0xD0 0xD1 0xD2 0xD3 0xD4 0xD5 0xD6 0xD7 0xD8 0xD9 0xDA 0xDB 0xDC 0xDD 0xDE 0xDF 0xE0 0xE1 0xE2 0xE3 0xE4 0xE5 0xE6 0xE7 0xE8 0xE9 0xEA 0xEB 0xEC 0xED 0xEE 0xEF 0xF0 0xF1 0xF2 0xF3 0xF4 0xF5 0xF6 0xF7 0xF7 0xF7 0xF7 0xF7>;
                default-brightness-level = <0x1D>;
                phandle = <0x7>;
            };
            gpio-keys {
                compatible = "gpio-keys";
                key-volumedown {
                    label = "Volume Down Key";
                    linux,code = <0x72>;
                    gpios = <0xFFFFFFFF 0x7C 0x1>;
                    debounce-interval = <0x2>;
                    wakeup-source;
                };
                key-volumeup {
                    label = "Volume Up Key";
                    linux,code = <0x73>;
                    gpios = <0xFFFFFFFF 0xA 0x0>;
                    debounce-interval = <0x2>;
                    wakeup-source;
                };
                key-power {
                    label = "Power Key";
                    linux,code = <0x74>;
                    gpios = <0xFFFFFFFF 0x1 0x1>;
                    debounce-interval = <0x2>;
                    wakeup-source;
                };
            };
            battery {
                compatible = "simple-battery";
                charge-full-design-microamp-hours = <0x2A6B60>;
                charge-term-current-microamp = <0x1D4C0>;
                constant_charge_voltage_max_microvolt = <0x426030>;
                factory-internal-resistance-micro-ohms = <0x4E200>;
                voltage-min-design-microvolt = <0x34A490>;
                ocv-capacity-celsius = <0x14>;
                ocv-capacity-table-0 = <0x421210 0x64 0x40D5A8 0x5F 0x3FEB48 0x5A 0x3F1088 0x55 0x3E4568 0x50 0x3D8DD0 0x4B 0x3CE5D8 0x46 0x3C5168 0x41 0x3BA970 0x3C 0x3AFD90 0x37 0x3A8860 0x32 0x3A2E88 0x2D 0x39E838 0x28 0x39B570 0x23 0x399630 0x1E 0x397308 0x19 0x393870 0x14 0x38DAB0 0xF 0x384258 0xA 0x37D110 0x5 0x33E140 0x0>;
                voltage-temp-table = <0x10B558 0x320 0xF0B90 0x352 0xD65B0 0x384 0xBD358 0x3B6 0xA5870 0x3E8 0x900B0 0x41A 0x7C830 0x44C 0x6B6C0 0x47E 0x5C490 0x4B0 0x4F1A0 0x4E2 0x43DF0 0x514 0x3A1B0 0x546 0x31CE0 0x578 0x2AB98 0x5AA 0x249F0 0x5DC 0x1F7E8 0x60E 0x1B198 0x640 0x17700 0x672>;
                capacity-temp-table = <0x19 0x64 0xA 0x61 0xFFFFFFF6 0x3C>;
                resistance-temp-table = <0x14 0x64 0xA 0xF3 0xFFFFFFF6 0x1D4>;
                charge-sdp-current-microamp = <0x7A120 0x7A120>;
                charge-dcp-current-microamp = <0x118C30 0x2DC6C0>;
                charge-cdp-current-microamp = <0x118C30 0x118C30>;
                charge-unknown-current-microamp = <0x7A120 0x7A120>;
                phandle = <0x5>;
            };
            charger-manager {
                compatible = "charger-manager";
                cm-name = "battery";
                cm-poll-mode = <0x2>;
                cm-poll-interval = <0x3A98>;
                cm-battery-stat = <0x2>;
                cm-fullbatt-vchkdrop-ms = <0x7530>;
                cm-fullbatt-vchkdrop-volt = <0xEA60>;
                cm-fullbatt-voltage = <0x421210>;
                cm-fullbatt-current = <0x1D4C0>;
                cm-fullbatt-capacity = <0x64>;
                cm-num-chargers = <0x1>;
                cm-chargers = "fan54015_charger";
                cm-fuel-gauge = "sc27xx-fgu";
                cm-battery-cold = <0xC8>;
                cm-battery-cold-in-minus;
                cm-battery-hot = <0x320>;
                cm-battery-temp-diff = <0x64>;
                cm-charging-max = <0x1499700>;
                cm-discharging-max = <0x2932E0>;
                cm-wdt-interval = <0x3C>;
                cm-shutdown-voltage = <0x2F4D60>;
                cm-tickle-time-out = <0x5DC>;
                cm-one-cap-time = <0x1E>;
                cm-charge-voltage-max = <0x632EA0>;
                cm-charge-voltage-drop = <0xAAE60>;
                cm-dcp-jeita-temp-table = <0x3E8 0x406 0x0 0x426030 0x47E 0x49C 0xAAE60 0x426030 0x5AA 0x58C 0x118C30 0x426030 0x640 0x622 0xAAE60 0x3E8FA0>;
                cm-sdp-jeita-temp-table = <0x3E8 0x406 0x0 0x426030 0x47E 0x49C 0x7A120 0x426030 0x5AA 0x58C 0x7A120 0x426030 0x640 0x622 0x7A120 0x3E8FA0>;
                cm-cdp-jeita-temp-table = <0x3E8 0x406 0x0 0x426030 0x47E 0x49C 0xAAE60 0x426030 0x5AA 0x58C 0x118C30 0x426030 0x640 0x622 0xAAE60 0x3E8FA0>;
                cm-unknown-jeita-temp-table = <0x3E8 0x406 0x0 0x426030 0x47E 0x49C 0x7A120 0x426030 0x5AA 0x58C 0x7A120 0x426030 0x640 0x622 0x7A120 0x3E8FA0>;
                monitored-battery = <0x5>;
                cm-capacity-track;
                cm-cap-remap-table = <0x1 0x2 0x3 0x2 0x3 0x2 0x62 0x63 0x2 0x63 0x64 0x3>;
                regulator@0 {
                    cm-regulator-name = "vddgen0";
                    cable@0 {
                        cm-cable-name = "USB";
                        extcon = <0xFFFFFFFF>;
                    };
                };
            };
        };
    };
    fragment@0 {
        target = <0xFFFFFFFF>;
        __overlay__ {
            bootargs_ext = "androidboot.hardware=s9863a1h10_go_32b androidboot.dtbo_idx=0";
        };
    };
    fragment@1 {
        target = <0xFFFFFFFF>;
        __overlay__ {
            faceid-mem@befee000 {
                reg = <0xBEFEE000 0x500000>;
                phandle = <0x1E>;
            };
            framebuffer@bf4ee000 {
                reg = <0xBF4EE000 0xA92000>;
                phandle = <0x1D>;
            };
        };
    };
    fragment@2 {
        target = <0xFFFFFFFF>;
        __overlay__ {
            extcon = <0xFFFFFFFF 0xFFFFFFFF>;
            vbus-supply = <0x6>;
        };
    };
    fragment@3 {
        target = <0xFFFFFFFF>;
        __overlay__ {
            monitored-battery = <0x5>;
            sprd,calib-resistance-real = <0x4E20>;
            sprd,calib-resistance-spec = <0x4E20>;
            first-calib-voltage = <0x36EE80>;
            first-calib-capacity = <0x28>;
        };
    };
    fragment@4 {
        target = <0xFFFFFFFF>;
        __overlay__ {
            sprd,backlight = <0x7>;
            sprd,surface-width = <0x2D0>;
            sprd,surface-height = <0x500>;
            avdd-gpio = <0xFFFFFFFF 0x4 0x0>;
            avee-gpio = <0xFFFFFFFF 0x5 0x0>;
            reset-gpio = <0xFFFFFFFF 0x32 0x0>;
        };
    };
    fragment@5 {
        target = <0xFFFFFFFF>;
        __overlay__ {
            status = "okay";
            clock-frequency = <0x61A80>;
            sensor-main@20 {
                compatible = "sprd,sensor-main";
                reg = <0x20>;
                clock-names = "clk_src", "sensor_eb", "clk_96m", "clk_76m8", "clk_48m", "clk_26m";
                clocks = <0xFFFFFFFF 0x30 0xFFFFFFFF 0xB 0xFFFFFFFF 0x4 0xFFFFFFFF 0x10 0xFFFFFFFF 0x5 0xFFFFFFFF>;
                vddio-supply = <0xFFFFFFFF>;
                vddcama-supply = <0xFFFFFFFF>;
                vddcamd-supply = <0xFFFFFFFF>;
                vddcammot-supply = <0xFFFFFFFF>;
                sprd,phyid = <0x1>;
                csi = <0xFFFFFFFF>;
                reset-gpios = <0xFFFFFFFF 0x2C 0x0>;
                power-down-gpios = <0xFFFFFFFF 0x2E 0x0>;
                phandle = <0x23>;
            };
        };
    };
    fragment@6 {
        target = <0xFFFFFFFF>;
        __overlay__ {
            status = "okay";
            clock-frequency = <0x61A80>;
            sensor-sub@20 {
                compatible = "sprd,sensor-sub";
                reg = <0x20>;
                clock-names = "clk_src", "sensor_eb", "clk_96m", "clk_76m8", "clk_48m", "clk_26m";
                clocks = <0xFFFFFFFF 0x31 0xFFFFFFFF 0xC 0xFFFFFFFF 0x4 0xFFFFFFFF 0x10 0xFFFFFFFF 0x5 0xFFFFFFFF>;
                vddio-supply = <0xFFFFFFFF>;
                vddcama-supply = <0xFFFFFFFF>;
                vddcamd-supply = <0xFFFFFFFF>;
                vddcammot-supply = <0xFFFFFFFF>;
                sprd,phyid = <0x4>;
                csi = <0xFFFFFFFF>;
                reset-gpios = <0xFFFFFFFF 0x29 0x0>;
                power-down-gpios = <0xFFFFFFFF 0x28 0x0>;
                phandle = <0x24>;
            };
            sensor-main2@6C {
                compatible = "sprd,sensor-main2";
                reg = <0x6C>;
                clock-names = "clk_src", "sensor_eb", "clk_96m", "clk_76m8", "clk_48m", "clk_26m";
                clocks = <0xFFFFFFFF 0x31 0xFFFFFFFF 0xC 0xFFFFFFFF 0x4 0xFFFFFFFF 0x10 0xFFFFFFFF 0x5 0xFFFFFFFF>;
                vddio-supply = <0xFFFFFFFF>;
                vddcama-supply = <0xFFFFFFFF>;
                vddcamd-supply = <0xFFFFFFFF>;
                vddcammot-supply = <0xFFFFFFFF>;
                sprd,phyid = <0x3>;
                csi = <0xFFFFFFFF>;
                dvdd-gpios = <0xFFFFFFFF 0x3E 0x0>;
                reset-gpios = <0xFFFFFFFF 0x2D 0x0>;
                power-down-gpios = <0xFFFFFFFF 0x2F 0x0>;
                phandle = <0x25>;
            };
            sensor-sub2@2a {
                compatible = "sprd,sensor-sub2";
                reg = <0x2A>;
                clock-names = "clk_src", "sensor_eb", "clk_96m", "clk_76m8", "clk_48m", "clk_26m";
                clocks = <0xFFFFFFFF 0x31 0xFFFFFFFF 0xC 0xFFFFFFFF 0x4 0xFFFFFFFF 0x10 0xFFFFFFFF 0x5 0xFFFFFFFF>;
                vddio-supply = <0xFFFFFFFF>;
                vddcama-supply = <0xFFFFFFFF>;
                vddcamd-supply = <0xFFFFFFFF>;
                vddcammot-supply = <0xFFFFFFFF>;
                sprd,phyid = <0x4>;
                csi = <0xFFFFFFFF>;
                reset-gpios = <0xFFFFFFFF 0x2D 0x0>;
                power-down-gpios = <0xFFFFFFFF 0x28 0x0>;
                phandle = <0x26>;
            };
        };
    };
    fragment@7 {
        target = <0xFFFFFFFF>;
        __overlay__ {
            status = "okay";
            touchscreen@38 {
                compatible = "adaptive-touchscreen";
                reg = <0x38>;
                gpios = <0xFFFFFFFF 0x91 0x0 0xFFFFFFFF 0x90 0x0>;
                controller = "focaltech,FT5436";
                virtualkeys = <0x244 0x3C 0x528 0x3C 0x2D 0xAC 0x168 0x528 0x3C 0x2D 0x9E 0x258 0x528 0x3C 0x2D>;
                surface-width = <0x2D0>;
                surface-height = <0x500>;
                firmware-auto-upgrade;
                private-data {
                    a8 = [5A];
                };
            };
        };
    };
    fragment@8 {
        target = <0xFFFFFFFF>;
        __overlay__ {
            status = "okay";
            charger@6a {
                compatible = "fairchild,fan54015_chg";
                reg = <0x6A>;
                phys = <0xFFFFFFFF>;
                monitored-battery = <0x5>;
                extcon = <0xFFFFFFFF>;
                phandle = <0x27>;
                otg-vbus {
                    regulator-name = "vddvbus";
                    phandle = <0x6>;
                };
            };
            flash-ic@63 {
                compatible = "sprd,flash-ocp8137";
                reg = <0x63>;
                sprd,flash-ic = <0x1FC9>;
                sprd,torch = <0x1>;
                sprd,preflash = <0x1>;
                sprd,highlight = <0x1>;
                sprd,torch-level = <0x80>;
                sprd,preflash-level = <0x80>;
                sprd,highlight-level = <0x80>;
                sprd,lvfm-enable = <0x1>;
                flash-torch-en-gpios = <0xFFFFFFFF 0x58 0x0>;
                flash-chip-en-gpios = <0xFFFFFFFF 0x59 0x0>;
                flash-en-gpios = <0xFFFFFFFF 0x4C 0x0>;
                flash-sync-gpios = <0xFFFFFFFF 0x8D 0x0>;
                phandle = <0x28>;
            };
        };
    };
    fragment@9 {
        target = <0xFFFFFFFF>;
        __overlay__ {
            status = "okay";
            clock-frequency = <0x61A80>;
        };
    };
    fragment@10 {
        target = <0xFFFFFFFF>;
        __overlay__ {
            sprd-scene = "boost", "lcdon", "lcdoff", "camlow", "camhigh", "camveryhigh";
            sprd-freq = <0x3A5 0x190 0xE9 0x190 0x26E 0x3A5>;
        };
    };
    fragment@11 {
        target = <0xFFFFFFFF>;
        __overlay__ {
            pinctrl-names = "gpio_121", "gpio_122", "gpio_123", "gpio_124", "gpio_125", "gpio_126", "gpio_144", "gpio_145", "gpio_146", "gpio_147", "shutdown";
            pinctrl-0 = <0x8>;
            pinctrl-1 = <0x9>;
            pinctrl-2 = <0xA>;
            pinctrl-3 = <0xB>;
            pinctrl-4 = <0xC>;
            pinctrl-5 = <0xD>;
            pinctrl-6 = <0xE>;
            pinctrl-7 = <0xF>;
            pinctrl-8 = <0x10>;
            pinctrl-9 = <0x11>;
            pinctrl-10 = <0x12 0x13 0x14 0x15 0x16 0x17>;
            keyout0 {
                pins = "SHARKL3_KEYOUT0";
                function = "func4";
                phandle = <0x8>;
            };
            keyout1 {
                pins = "SHARKL3_KEYOUT1";
                function = "func4";
                phandle = <0x9>;
            };
            keyout2 {
                pins = "SHARKL3_KEYOUT2";
                function = "func4";
                phandle = <0xA>;
            };
            keyin0 {
                pins = "SHARKL3_KEYIN0";
                function = "func4";
                phandle = <0xB>;
            };
            keyin1 {
                pins = "SHARKL3_KEYIN1";
                function = "func4";
                phandle = <0xC>;
            };
            keyin2 {
                pins = "SHARKL3_KEYIN2";
                function = "func4";
                phandle = <0xD>;
            };
            extint0 {
                pins = "SHARKL3_EXTINT0";
                function = "func4";
                phandle = <0xE>;
            };
            extint1 {
                pins = "SHARKL3_EXTINT1";
                function = "func4";
                phandle = <0xF>;
            };
            scl3 {
                pins = "SHARKL3_SCL3";
                function = "func4";
                phandle = <0x10>;
            };
            sda3 {
                pins = "SHARKL3_SDA3";
                function = "func4";
                phandle = <0x11>;
            };
            rfsen0 {
                pins = "SHARKL3_RFSEN0";
                function = "func4";
                phandle = <0x12>;
            };
            rfsck0 {
                pins = "SHARKL3_RFSCK0";
                function = "func4";
                phandle = <0x13>;
            };
            rfsda0 {
                pins = "SHARKL3_RFSDA0";
                function = "func4";
                phandle = <0x14>;
            };
            rfsen1 {
                pins = "SHARKL3_RFSEN1";
                function = "func4";
                phandle = <0x15>;
            };
            rfsck1 {
                pins = "SHARKL3_RFSCK1";
                function = "func4";
                phandle = <0x16>;
            };
            rfsda1 {
                pins = "SHARKL3_RFSDA1";
                function = "func4";
                phandle = <0x17>;
            };
        };
    };
    fragment@12 {
        target = <0xFFFFFFFF>;
        __overlay__ {
            cd-gpios = <0xFFFFFFFF 0x9 0x1>;
        };
    };
    fragment@13 {
        target = <0xFFFFFFFF>;
        __overlay__ {
            hwdvfs_dev = <0x18 0x19 0x1A>;
            cluster@0 {
                reg = <0x0>;
                dcdc-ctrl = <0x1B>;
                phandle = <0x18>;
            };
            cluster@1 {
                reg = <0x1>;
                dcdc-ctrl = <0x1C>;
                phandle = <0x19>;
            };
            dsu@0 {
                reg = <0x0>;
                dcdc-ctrl = <0x1C>;
                phandle = <0x1A>;
            };
            dcdc-controller@0 {
                reg = <0x0 0x0>;
                volt-via-adi;
                volt-hold-us = <0x32>;
                volt-pause-us = <0x5>;
                volt-timeout-us = <0x320>;
                volt-stable-us = <0x5>;
                volt-max-step-microvolt = <0x61A8>;
                phandle = <0x1C>;
            };
            dcdc-controller@1 {
                reg = <0x1 0x2>;
                volt-via-i2c;
                volt-hold-us = <0x19>;
                volt-pause-us = <0x14>;
                volt-timeout-us = <0x320>;
                volt-stable-us = <0x19>;
                volt-max-step-microvolt = <0x124F84>;
                phandle = <0x1B>;
            };
        };
    };
    fragment@14 {
        target = <0xFFFFFFFF>;
        __overlay__ {
            regulator-always-on;
        };
    };
    fragment@15 {
        target = <0xFFFFFFFF>;
        __overlay__ {
            regulator-always-on;
        };
    };
    fragment@16 {
        target = <0xFFFFFFFF>;
        __overlay__ {
            regulator-always-on;
        };
    };
    fragment@17 {
        target = <0xFFFFFFFF>;
        __overlay__ {
            regulator-always-on;
        };
    };
    fragment@18 {
        target = <0xFFFFFFFF>;
        __overlay__ {
            status = "disabled";
        };
    };
    fragment@19 {
        target = <0xFFFFFFFF>;
        __overlay__ {
            heap@3 {
                reg = <0x3>;
                label = "carveout_fb";
                type = <0x2>;
                memory-region = <0x1D>;
            };
            heap@4 {
                reg = <0x4>;
                label = "carveout_fd";
                type = <0x2>;
                memory-region = <0x1E>;
            };
        };
    };
    __symbols__ {
        lcd_nt35695_truly_mipi_fhd = "/fragment/__overlay__/lcds/lcd_nt35695_truly_mipi_fhd";
        nt35695_truly_timing0 = "/fragment/__overlay__/lcds/lcd_nt35695_truly_mipi_fhd/display-timings/timing0";
        lcd_nt35532_truly_mipi_fhd = "/fragment/__overlay__/lcds/lcd_nt35532_truly_mipi_fhd";
        nt35532_truly_timing0 = "/fragment/__overlay__/lcds/lcd_nt35532_truly_mipi_fhd/display-timings/timing0";
        lcd_nt35596_boe_mipi_fhd = "/fragment/__overlay__/lcds/lcd_nt35596_boe_mipi_fhd";
        nt35596_boe_timing0 = "/fragment/__overlay__/lcds/lcd_nt35596_boe_mipi_fhd/display-timings/timing0";
        lcd_dummy_mipi_hd = "/fragment/__overlay__/lcds/lcd_dummy_mipi_hd";
        dummy_timing0 = "/fragment/__overlay__/lcds/lcd_dummy_mipi_hd/display-timings/timing0";
        pwm_backlight = "/fragment/__overlay__/sprd_backlight";
        bat = "/fragment/__overlay__/battery";
        fd_reserved = "/fragment@1/__overlay__/faceid-mem@befee000";
        fb_reserved = "/fragment@1/__overlay__/framebuffer@bf4ee000";
        sensor_main = "/fragment@5/__overlay__/sensor-main@20";
        sensor_sub = "/fragment@6/__overlay__/sensor-sub@20";
        sensor_main2 = "/fragment@6/__overlay__/sensor-main2@6C";
        sensor_sub2 = "/fragment@6/__overlay__/sensor-sub2@2a";
        fan54015_chg = "/fragment@8/__overlay__/charger@6a";
        vddvbus = "/fragment@8/__overlay__/charger@6a/otg-vbus";
        flash_ic = "/fragment@8/__overlay__/flash-ic@63";
        gpio_121 = "/fragment@11/__overlay__/keyout0";
        gpio_122 = "/fragment@11/__overlay__/keyout1";
        gpio_123 = "/fragment@11/__overlay__/keyout2";
        gpio_124 = "/fragment@11/__overlay__/keyin0";
        gpio_125 = "/fragment@11/__overlay__/keyin1";
        gpio_126 = "/fragment@11/__overlay__/keyin2";
        gpio_144 = "/fragment@11/__overlay__/extint0";
        gpio_145 = "/fragment@11/__overlay__/extint1";
        gpio_146 = "/fragment@11/__overlay__/scl3";
        gpio_147 = "/fragment@11/__overlay__/sda3";
        shutdown0 = "/fragment@11/__overlay__/rfsen0";
        shutdown1 = "/fragment@11/__overlay__/rfsck0";
        shutdown2 = "/fragment@11/__overlay__/rfsda0";
        shutdown3 = "/fragment@11/__overlay__/rfsen1";
        shutdown4 = "/fragment@11/__overlay__/rfsck1";
        shutdown5 = "/fragment@11/__overlay__/rfsda1";
        hwdvfs_cluster0 = "/fragment@13/__overlay__/cluster@0";
        hwdvfs_cluster1 = "/fragment@13/__overlay__/cluster@1";
        hwdvfs_dsu = "/fragment@13/__overlay__/dsu@0";
        dcdc_ctrl0 = "/fragment@13/__overlay__/dcdc-controller@0";
        dcdc_ctrl1 = "/fragment@13/__overlay__/dcdc-controller@1";
    };
    __fixups__ {
        ap_gpio = "/fragment/__overlay__/fingerprint@0:fpint-gpios:0", "/fragment/__overlay__/gpio-keys/key-volumedown:gpios:0", "/fragment@4/__overlay__:avdd-gpio:0", "/fragment@4/__overlay__:avee-gpio:0", "/fragment@4/__overlay__:reset-gpio:0", "/fragment@5/__overlay__/sensor-main@20:reset-gpios:0", "/fragment@5/__overlay__/sensor-main@20:power-down-gpios:0", "/fragment@6/__overlay__/sensor-sub@20:reset-gpios:0", "/fragment@6/__overlay__/sensor-sub@20:power-down-gpios:0", "/fragment@6/__overlay__/sensor-main2@6C:dvdd-gpios:0", "/fragment@6/__overlay__/sensor-main2@6C:reset-gpios:0", "/fragment@6/__overlay__/sensor-main2@6C:power-down-gpios:0", "/fragment@6/__overlay__/sensor-sub2@2a:reset-gpios:0", "/fragment@6/__overlay__/sensor-sub2@2a:power-down-gpios:0", "/fragment@7/__overlay__/touchscreen@38:gpios:0", "/fragment@7/__overlay__/touchscreen@38:gpios:12", "/fragment@8/__overlay__/flash-ic@63:flash-torch-en-gpios:0", "/fragment@8/__overlay__/flash-ic@63:flash-chip-en-gpios:0", "/fragment@8/__overlay__/flash-ic@63:flash-en-gpios:0", "/fragment@8/__overlay__/flash-ic@63:flash-sync-gpios:0";
        pwms = "/fragment/__overlay__/sprd_backlight:pwms:0";
        pmic_eic = "/fragment/__overlay__/gpio-keys/key-volumeup:gpios:0", "/fragment/__overlay__/gpio-keys/key-power:gpios:0";
        pmic_typec = "/fragment/__overlay__/charger-manager/regulator@0/cable@0:extcon:0", "/fragment@2/__overlay__:extcon:4";
        chosen = "/fragment@0:target:0";
        reserved_memory = "/fragment@1:target:0";
        usb = "/fragment@2:target:0";
        extcon_gpio = "/fragment@2/__overlay__:extcon:0", "/fragment@8/__overlay__/charger@6a:extcon:0";
        pmic_fgu = "/fragment@3:target:0";
        panel = "/fragment@4:target:0";
        i2c0 = "/fragment@5:target:0";
        aon_clk = "/fragment@5/__overlay__/sensor-main@20:clocks:0", "/fragment@6/__overlay__/sensor-sub@20:clocks:0", "/fragment@6/__overlay__/sensor-main2@6C:clocks:0", "/fragment@6/__overlay__/sensor-sub2@2a:clocks:0";
        mm_gate = "/fragment@5/__overlay__/sensor-main@20:clocks:8", "/fragment@6/__overlay__/sensor-sub@20:clocks:8", "/fragment@6/__overlay__/sensor-main2@6C:clocks:8", "/fragment@6/__overlay__/sensor-sub2@2a:clocks:8";
        pll = "/fragment@5/__overlay__/sensor-main@20:clocks:16", "/fragment@5/__overlay__/sensor-main@20:clocks:24", "/fragment@5/__overlay__/sensor-main@20:clocks:32", "/fragment@6/__overlay__/sensor-sub@20:clocks:16", "/fragment@6/__overlay__/sensor-sub@20:clocks:24", "/fragment@6/__overlay__/sensor-sub@20:clocks:32", "/fragment@6/__overlay__/sensor-main2@6C:clocks:16", "/fragment@6/__overlay__/sensor-main2@6C:clocks:24", "/fragment@6/__overlay__/sensor-main2@6C:clocks:32", "/fragment@6/__overlay__/sensor-sub2@2a:clocks:16", "/fragment@6/__overlay__/sensor-sub2@2a:clocks:24", "/fragment@6/__overlay__/sensor-sub2@2a:clocks:32";
        ext_26m = "/fragment@5/__overlay__/sensor-main@20:clocks:40", "/fragment@6/__overlay__/sensor-sub@20:clocks:40", "/fragment@6/__overlay__/sensor-main2@6C:clocks:40", "/fragment@6/__overlay__/sensor-sub2@2a:clocks:40";
        vddcamio = "/fragment@5/__overlay__/sensor-main@20:vddio-supply:0", "/fragment@6/__overlay__/sensor-sub@20:vddio-supply:0", "/fragment@6/__overlay__/sensor-main2@6C:vddio-supply:0", "/fragment@6/__overlay__/sensor-sub2@2a:vddio-supply:0";
        vddcama = "/fragment@5/__overlay__/sensor-main@20:vddcama-supply:0", "/fragment@6/__overlay__/sensor-sub@20:vddcama-supply:0", "/fragment@6/__overlay__/sensor-main2@6C:vddcama-supply:0", "/fragment@6/__overlay__/sensor-sub2@2a:vddcama-supply:0";
        vddcamd = "/fragment@5/__overlay__/sensor-main@20:vddcamd-supply:0", "/fragment@6/__overlay__/sensor-sub@20:vddcamd-supply:0", "/fragment@6/__overlay__/sensor-main2@6C:vddcamd-supply:0", "/fragment@6/__overlay__/sensor-sub2@2a:vddcamd-supply:0";
        vddcammot = "/fragment@5/__overlay__/sensor-main@20:vddcammot-supply:0", "/fragment@6/__overlay__/sensor-sub@20:vddcammot-supply:0", "/fragment@6/__overlay__/sensor-main2@6C:vddcammot-supply:0", "/fragment@6/__overlay__/sensor-sub2@2a:vddcammot-supply:0";
        csi0 = "/fragment@5/__overlay__/sensor-main@20:csi:0", "/fragment@6/__overlay__/sensor-sub@20:csi:0";
        i2c1 = "/fragment@6:target:0";
        csi1 = "/fragment@6/__overlay__/sensor-main2@6C:csi:0";
        csi2 = "/fragment@6/__overlay__/sensor-sub2@2a:csi:0";
        i2c3 = "/fragment@7:target:0";
        i2c4 = "/fragment@8:target:0";
        hsphy = "/fragment@8/__overlay__/charger@6a:phys:0";
        i2c7 = "/fragment@9:target:0";
        ddr_dfs = "/fragment@10:target:0";
        pin_controller = "/fragment@11:target:0";
        sdio0 = "/fragment@12:target:0";
        eic_sync = "/fragment@12/__overlay__:cd-gpios:0";
        sprd_hwdvfs = "/fragment@13:target:0";
        vdd18 = "/fragment@14:target:0";
        vddrf18 = "/fragment@15:target:0";
        vddrf125 = "/fragment@16:target:0";
        vddldomem = "/fragment@17:target:0";
        vddsim2 = "/fragment@18:target:0";
        ion = "/fragment@19:target:0";
    };
    __local_fixups__ {
        fragment {
            __overlay__ {
                lcds {
                    lcd_nt35695_truly_mipi_fhd {
                        display-timings {
                            native-mode = <0x0>;
                        };
                    };
                    lcd_nt35532_truly_mipi_fhd {
                        display-timings {
                            native-mode = <0x0>;
                        };
                    };
                    lcd_nt35596_boe_mipi_fhd {
                        display-timings {
                            native-mode = <0x0>;
                        };
                    };
                    lcd_dummy_mipi_hd {
                        display-timings {
                            native-mode = <0x0>;
                        };
                    };
                };
                charger-manager {
                    monitored-battery = <0x0>;
                };
            };
        };
        fragment@2 {
            __overlay__ {
                vbus-supply = <0x0>;
            };
        };
        fragment@3 {
            __overlay__ {
                monitored-battery = <0x0>;
            };
        };
        fragment@4 {
            __overlay__ {
                sprd,backlight = <0x0>;
            };
        };
        fragment@8 {
            __overlay__ {
                charger@6a {
                    monitored-battery = <0x0>;
                };
            };
        };
        fragment@11 {
            __overlay__ {
                pinctrl-0 = <0x0>;
                pinctrl-1 = <0x0>;
                pinctrl-2 = <0x0>;
                pinctrl-3 = <0x0>;
                pinctrl-4 = <0x0>;
                pinctrl-5 = <0x0>;
                pinctrl-6 = <0x0>;
                pinctrl-7 = <0x0>;
                pinctrl-8 = <0x0>;
                pinctrl-9 = <0x0>;
                pinctrl-10 = <0x0 0x4 0x8 0xC 0x10 0x14>;
            };
        };
        fragment@13 {
            __overlay__ {
                hwdvfs_dev = <0x0 0x4 0x8>;
                cluster@0 {
                    dcdc-ctrl = <0x0>;
                };
                cluster@1 {
                    dcdc-ctrl = <0x0>;
                };
                dsu@0 {
                    dcdc-ctrl = <0x0>;
                };
            };
        };
        fragment@19 {
            __overlay__ {
                heap@3 {
                    memory-region = <0x0>;
                };
                heap@4 {
                    memory-region = <0x0>;
                };
            };
        };
    };
};
